# moonlight_application register map
Vendor: Nordic Semiconductor; Series: lumos; File version: 1
CPU: CM33 r0p4, little endian, MPU, FPU, 3 interrupt priority bits, 176 interrupts, 4 SAU regions
Registers are 32-bit, read-write, reset 0x0 unless marked. A register's access mark holds for its fields unless they carry their own. Offsets are from the block's base; [hi:lo] are bit positions; lines under a group give offsets from that group; 'fields as' and 'values as' point back to an identical list.

## GLOBAL_GPIOHSPADCTRL_NS — GPIO high-speed pad control 0
Base 0x40050400
Same registers: GLOBAL_GPIOHSPADCTRL_S 0x50050400
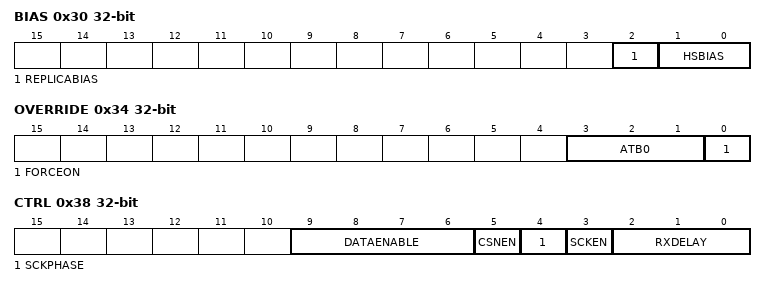
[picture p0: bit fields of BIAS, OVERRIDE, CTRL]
0x30 BIAS — Bias control
  [2] REPLICABIAS — Bias setting for replica pad
  [1:0] HSBIAS — Bias setting for high-speed pad
0x34 OVERRIDE — Override control
  [3:1] ATB0 — ATB0 settings
    7=BiasTrim (Unspecified); 6=BiasSupply (Unspecified); 5=BiasPTAT (Unspecified)
  [0] FORCEON
0x38 CTRL — HS pad control register
  [9:6] DATAENABLE — Enable re-clocking for data bit 0-3 through pad-sync module
  [5] CSNEN — CSN enable
  [4] SCKPHASE
  [3] SCKEN — Enable SCK
  [2:0] RXDELAY — RXDELAY setting

## GLOBAL_CTRLAP_NS — Control access port 0
Base 0x40052000
Same registers: GLOBAL_CTRLAP_S 0x50052000
0x100 EVENTS_RXREADY — RXSTATUS is changed to DataPending.
  [0] EVENTS_RXREADY
    0=NotGenerated (Event not generated); 1=Generated (Event generated)
0x104 EVENTS_TXDONE — TXSTATUS is changed to NoDataPending.
  [0] EVENTS_TXDONE
    values as EVENTS_RXREADY.EVENTS_RXREADY
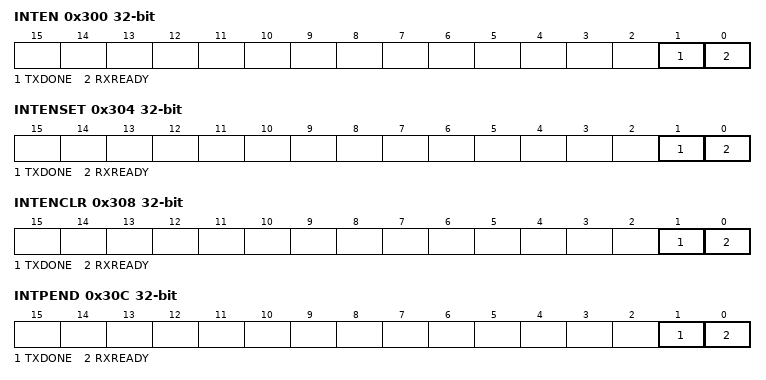
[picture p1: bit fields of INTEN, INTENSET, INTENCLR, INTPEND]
0x300 INTEN — Enable or disable interrupt
  [1] TXDONE — Enable or disable interrupt for event TXDONE
    0=Disabled; 1=Enabled
  [0] RXREADY — Enable or disable interrupt for event RXREADY
    0=Disabled; 1=Enabled
0x304 INTENSET — Enable interrupt
  [1] TXDONE — Write '1' to enable interrupt for event TXDONE
    on read: 0=Disabled (Read: Disabled); 1=Enabled (Read: Enabled) | on write: 1=Set (Enable)
  [0] RXREADY — Write '1' to enable interrupt for event RXREADY
    values as TXDONE
0x308 INTENCLR — Disable interrupt
  [1] TXDONE — Write '1' to disable interrupt for event TXDONE
    on read: 0=Disabled (Read: Disabled); 1=Enabled (Read: Enabled) | on write: 1=Clear (Disable)
  [0] RXREADY — Write '1' to disable interrupt for event RXREADY
    values as TXDONE
0x30C INTPEND ro — Pending interrupts
  [1] TXDONE — Read pending status of interrupt for event TXDONE
    on read: 0=NotPending (Read: Not pending); 1=Pending (Read: Pending)
  [0] RXREADY — Read pending status of interrupt for event RXREADY
    values as TXDONE
0x400 MAILBOX group — Unspecified
  0x00 RXDATA ro — Data sent from the debugger to the CPU.
    [31:0] RXDATA — Data received from debugger.
  0x04 RXSTATUS ro — Status to indicate if data sent from the debugger to the CPU has been read.
    [0] RXSTATUS — Status of data in register RXDATA.
      0=NoDataPending (No data is pending in register RXDATA.); 1=DataPending (Data is pending in register RXDATA.)
  0x80 TXDATA — Data sent from the CPU to the debugger.
    [31:0] TXDATA — Data sent to debugger.
  0x84 TXSTATUS ro — Status to indicate if data sent from the CPU to the debugger has been read.
    [0] TXSTATUS — Status of data in register TXDATA.
      0=NoDataPending (No data is pending in register TXDATA.); 1=DataPending (Data is pending in register TXDATA.)
0x500 ERASEPROTECT group — Unspecified
  0x00 LOCK rw-once — This register locks the ERASEPROTECT.DISABLE register from being written until next reset.
    [0] LOCK — Lock ERASEPROTECT.DISABLE register from being written until next reset.
      0=Unlocked (Register ERASEPROTECT.DISABLE is writeable.); 1=Locked (Register ERASEPROTECT.DISABLE is read-only.)
  0x04 DISABLE rw-once — This register disables the ERASEPROTECT register and performs an ERASEALL operation.
    [31:0] KEY — The ERASEALL sequence is initiated if the value of the KEY fields are non-zero and the KEY fields match on both the CPU and debugger sides.
0x520 RESET wo — System reset request.
  [2:0] RESET — Reset request
    0=No reset is generated; 1=SoftReset (Perform a device soft reset); 2=HardReset (Perform a device hard reset); 4=PinReset (Perform a device pin reset)
0x600 INFO group — Unspecified
  0x00 PARTNO write-once — Part number of the device.
    [31:0] PARTNO — Part number.
  0x04 HWREVISION write-once — Hardware Revision of the device.
    [31:0] ID — Part Variant.
